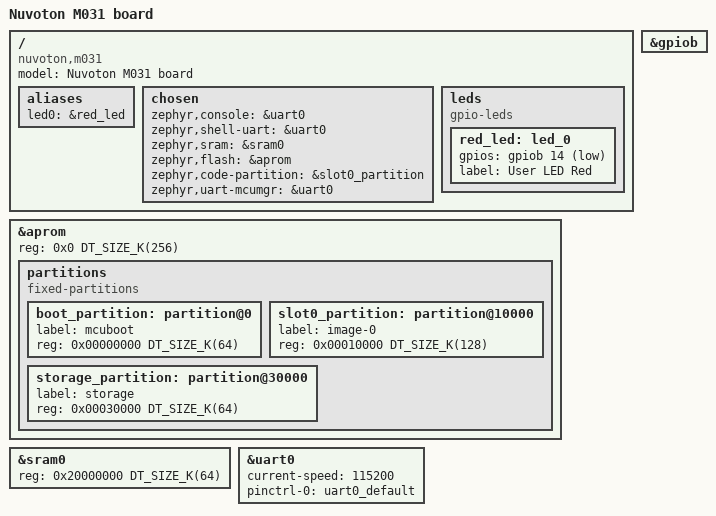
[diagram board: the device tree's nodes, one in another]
/*
 * Copyright (c) 2020 Linumiz
 *
 * SPDX-License-Identifier: Apache-2.0
 */

/dts-v1/;
#include <nuvoton/m03x.dtsi>
#include "nuvoton_m031-pinctrl.dtsi"
#include <zephyr/dt-bindings/input/input-event-codes.h>

/ {
	model = "Nuvoton M031 board";
	compatible = "nuvoton,m031", "nuvoton,m031";

	aliases {
		led0 = &red_led;
	};

	chosen {
		zephyr,console = &uart0;
		zephyr,shell-uart = &uart0;
		zephyr,sram = &sram0;
		zephyr,flash = &aprom;

		zephyr,code-partition = &slot0_partition;
        zephyr,uart-mcumgr = &uart0;
	};

	leds {
		compatible = "gpio-leds";
		red_led: led_0 {
			gpios = <&gpiob 14 GPIO_ACTIVE_LOW>;
			label = "User LED Red";
		};
	};
};

&aprom {
	reg = <0x0 DT_SIZE_K(256)>;

	partitions {
		compatible = "fixed-partitions";
		#address-cells = <1>;
		#size-cells = <1>;

		boot_partition: partition@0 {
			label = "mcuboot";
			reg = <0x00000000 DT_SIZE_K(64)>;
		};
		slot0_partition: partition@10000 {
			label = "image-0";
			reg = <0x00010000 DT_SIZE_K(128)>;
		};
		storage_partition: partition@30000 {
			label = "storage";
			reg = <0x00030000 DT_SIZE_K(64)>;
		};
	};
};

&sram0 {
	reg = <0x20000000 DT_SIZE_K(64)>;
};

&gpiob {
	status = "okay";
};

&uart0 {
	current-speed = <115200>;
	status = "okay";
	pinctrl-0 = <&uart0_default>;
	pinctrl-names = "default";
};
